# D1H register map
Vendor: Allwinner; File version: 1.0
Registers are 32-bit, read-write, reset 0x0 unless marked. A register's access mark holds for its fields unless they carry their own. Offsets are from the block's base; [hi:lo] are bit positions; {n}, {i} and the like mark numbered series.

## UART[{n}] — Universal Asynchronous Receiver Transmitter
Base 0x02500000; array of 6, step 0x400
0x00 rbr ro — UART Receive Buffer Register
  [7:0] rbr
0x00 thr wo — UART Transmit Holding Register
  [7:0] thr
0x00 dll — UART Divisor Latch Low Register
  [7:0] dll
0x04 dlh — UART Divisor Latch High Register
  [7:0] dlh
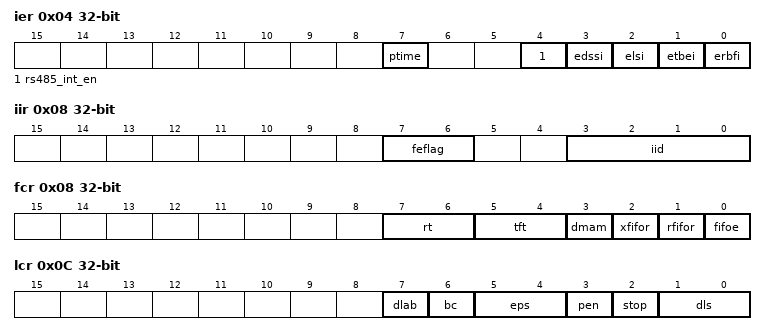
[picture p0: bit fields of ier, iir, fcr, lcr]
0x04 ier — UART Interrupt Enable Register
  [all] fields
    0=DISABLE; 1=ENABLE
  [7] ptime — Programmable THRE Interrupt Mode Enable
  [4] rs485_int_en — RS485 Interrupt Enable
  [3] edssi — Enable Modem Status Interrupt
  [2] elsi — Enable Receiver Line Status Interrupt
  [1] etbei — Enable Transmit Holding Register Empty Interrupt
  [0] erbfi — Enable Received Data Available Interrupt
0x08 iir ro — UART Interrupt Identity Register
  [7:6] feflag — FIFOs Enable Flag
    0=DISABLE; 3=ENABLE
  [3:0] iid — Interrupt ID
    0=MODEM_STATUS; 1=NO_INTERRUPT_PENDING; 2=THR_EMPTY; 3=RS485_INTERRUPT; 4=RECEIVED_DATA_AVAILABLE; 6=RECEIVER_LINE_STATUS; 7=BUSY_DETECT; 12=CHARACTER_TIMEOUT
0x08 fcr wo — UART FIFO Control Register
  [7:6] rt
    0=ONE_CHARACTER; 1=QUARTER_FULL; 2=HALF_FULL; 3=TWO_LESS_THAN_FULL
  [5:4] tft
    0=EMPTY; 1=TWO_CHARACTERS; 2=QUARTER_FULL; 3=HALF_FULL
  [3] dmam
    0=MODE_0; 1=MODE_1
  [2] xfifor
  [1] rfifor
  [0] fifoe
0x0C lcr — UART Line Control Register
  [7] dlab — Divisor Latch Access Bit
    0=RX_BUFFER; 1=DIVISOR_LATCH
  [6] bc — Break Control Bit
  [5:4] eps — Even Parity Select
    0=ODD; 1=EVEN; 2=RS485_DATA; 3=RS485_ADDR
  [3] pen — Parity Enable
    0=DISABLED; 1=ENABLED
  [2] stop — Number of stop bits
    0=ONE (1 stop bit); 1=TWO (1.5 stop bits when DLS(LCR[1:0]) is zero, else 2 stop bits)
  [1:0] dls — Data Length Select
    0=FIVE (5 bits); 1=SIX (6 bits); 2=SEVEN (7 bits); 3=EIGHT (8 bits)
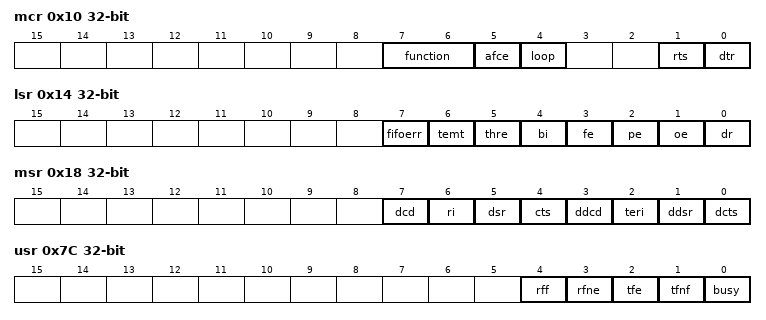
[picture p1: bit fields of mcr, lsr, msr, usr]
0x10 mcr — UART Modem Control Register
  [7:6] function — UART Function: Select IrDA or RS485
    0=UART; 1=IR_DA_SIR; 2=RS485
  [5] afce — Auto Flow Control Enable
    0=DISABLED; 1=ENABLED
  [4] loop — Loop Back Mode
    0=NORMAL; 1=LOOP_BACK
  [1] rts — Request to Send
    0=DEASSERTED; 1=ASSERTED
  [0] dtr — Data Terminal Ready
    0=DEASSERTED; 1=ASSERTED
0x14 lsr ro — UART Line Status Register
  [7] fifoerr — RX Data Error in FIFO
    1=ERROR
  [6] temt — Transmitter Empty
    1=EMPTY
  [5] thre — TX Holding Register Empty
    1=EMPTY
  [4] bi — Break Interrupt
  [3] fe — Framing Error
    1=ERROR
  [2] pe — Parity Error
    1=ERROR
  [1] oe — Overrun Error
    1=ERROR
  [0] dr — Data Ready
    1=READY
0x18 msr ro — UART Modem Status Register
  [7] dcd — Line State of Data Carrier Detect
    0=DEASSERTED; 1=ASSERTED
  [6] ri — Line State of Ring Indicator
    0=DEASSERTED; 1=ASSERTED
  [5] dsr — Line State of Data Set Ready
    0=DEASSERTED; 1=ASSERTED
  [4] cts — Line State of Clear To Send
    0=DEASSERTED; 1=ASSERTED
  [3] ddcd — Delta Data Carrier Detect
    0=NO_CHANGE; 1=CHANGE
  [2] teri — Trailing Edge Ring Indicator
    0=NO_CHANGE; 1=CHANGE
  [1] ddsr — Delta Data Set Ready
    0=NO_CHANGE; 1=CHANGE
  [0] dcts — Delta Clear to Send
    0=NO_CHANGE; 1=CHANGE
0x1C sch — UART Scratch Register
  [7:0] scratch
0x7C usr ro — UART Status Register
  [4] rff — RX FIFO Full
    0=NOT_FULL; 1=FULL
  [3] rfne — RX FIFO Not Empty
    0=EMPTY; 1=NOT_EMPTY
  [2] tfe — TX FIFO Empty
    0=NOT_EMPTY; 1=EMPTY
  [1] tfnf — TX FIFO Not Full
    0=FULL; 1=NOT_FULL
  [0] busy — UART Busy Bit
    0=IDLE; 1=BUSY
0x80 tfl ro — UART Transmit FIFO Level Register
  [8:0] tfl — TX FIFO Level
0x84 rfl ro — UART Receive FIFO Level Register
  [8:0] rfl — RX FIFO Level
0x88 hsk — UART DMA Handshake Configuration Register
  [7:0] hsk — Handshake configuration
    165=WAIT_CYCLE; 229=HANDSHAKE
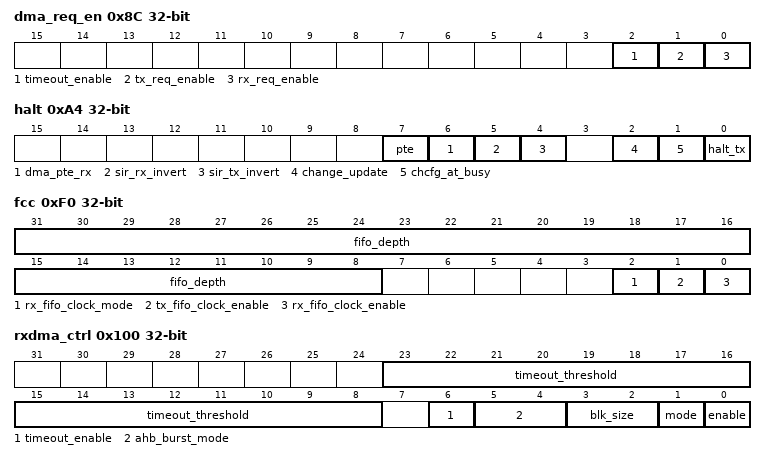
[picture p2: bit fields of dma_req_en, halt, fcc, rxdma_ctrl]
0x8C dma_req_en — UART DMA Request Enable Register
  [all] fields
    0=DISABLE; 1=ENABLE
  [2] timeout_enable — DMA Timeout Enable
  [1] tx_req_enable — DMA TX REQ Enable
  [0] rx_req_enable — DMA RX REQ Enable
0xA4 halt — UART Halt TX Register
  [7] pte — The sending of TX_REQ
  [6] dma_pte_rx — The Transmission of RX_DRQ
  [5] sir_rx_invert — SIR RX Pulse Polarity Invert
    0=NOT_INVERT; 1=INVERT
  [4] sir_tx_invert — SIR TX Pulse Polarity Invert
    0=NOT_INVERT; 1=INVERT
  [2] change_update
    0=FINISHED; 1=UPDATE_TRIGGER
  [1] chcfg_at_busy
    0=DISABLE; 1=ENABLE
  [0] halt_tx
    0=DISABLED; 1=ENABLED
0xB0 dbg_dll ro — UART Debug DLL Register
  [7:0] dbg_dll
0xB4 dbg_dlh ro — UART Debug DLH Register
  [7:0] dbg_dlh
0xF0 fcc — UART FIFO Clock Control Register
  [31:8] fifo_depth ro
  [2] rx_fifo_clock_mode
    0=WR_APB (Sync mode, writing/reading clocks use apb clock); 1=W_APB_R_AHB (Sync mode, writing clock uses apb clock, reading clock uses ahb clock)
  [1] tx_fifo_clock_enable
    0=DISABLE; 1=ENABLE
  [0] rx_fifo_clock_enable
    0=DISABLE; 1=ENABLE
0x100 rxdma_ctrl — UART RXDMA Control Register
  [23:8] timeout_threshold — RXDMA Timeout Threshold . Unit is 1 UART bit time
  [6] timeout_enable — RXDMA Timeout Enable
  [5:4] ahb_burst_mode — Set for AHB port burst supported
    0=SINGLE; 1=INCR4; 2=INCR8; 3=INCR16
  [3:2] blk_size
    0=B8; 1=B16; 2=B32; 3=B64
  [1] mode
    0=CONTINOUS; 1=LIMITED
  [0] enable
    0=DISABLE; 1=ENABLE
0x104 rxdma_str — UART RXDMA Start Register
  [0] start
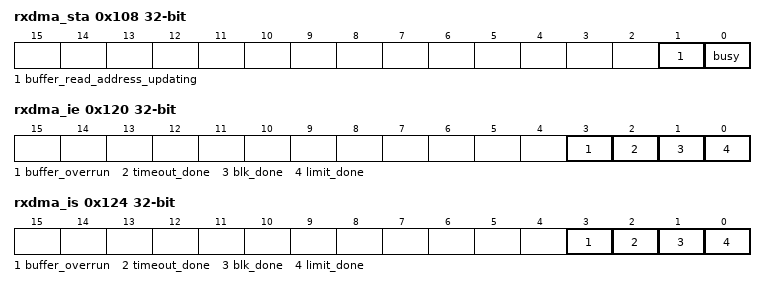
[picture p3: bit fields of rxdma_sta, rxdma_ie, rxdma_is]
0x108 rxdma_sta — UART RXDMA Status Register
  [1] buffer_read_address_updating
    0=READY; 1=BUSY
  [0] busy
    0=IDLE; 1=BUSY
0x10C rxdma_lmt — UART RXDMA Limit Register
  [15:0] limit_size
0x110 rxdma_saddrl — UART RXDMA Buffer Start Address Low Register
0x114 rxdma_saddrh — UART RXDMA Buffer Start Address High Register
  [1:0] saddr — RXDMA Buffer Start Address [33:32]
0x118 rxdma_bl — UART RXDMA Buffer Length Register
  [15:0] buffer_length
0x120 rxdma_ie — UART RXDMA Interrupt Enable Register
  [3] buffer_overrun, [2] timeout_done, [1] blk_done, [0] limit_done
0x124 rxdma_is — UART RXDMA Interrupt Status Register
  [3] buffer_overrun, [2] timeout_done, [1] blk_done, [0] limit_done
0x128 rxdma_waddrl ro — UART RXDMA Write Address Low Register
0x12C rxdma_waddrh ro — UART RXDMA Write Address High Register
  [1:0] waddr — RXDMA Current Write Address [33:32]
0x130 rxdma_raddrl — UART RXDMA Read Address Low Register
0x134 rxdma_raddrh — UART RXDMA Read Address High Register
  [1:0] raddr — RXDMA Current Read Address [33:32]
0x138 rxdma_dcnt — UART RXDMA Data Count Register
  [15:0] data_count
